# ELM0 register map
Vendor: Texas Instruments
Peripheral module from a debugger description file (folder J7VCL).
Registers are 32-bit, read-only, reset values left out (the file's numbers can be read two ways) unless marked. A register's access mark holds for its fields unless they carry their own. Offsets are as the file gives them; lines under a group give offsets from that group; [hi:lo] are bit positions; {n}, {i} and the like mark numbered series; 'fields as' and 'values as' point back to an identical list; <NAME> marks a mode.

## ELM0
0x5380000 ELM_REVISION — This register contains the IP revision code. (A write to or reset of this register has no effect.)
  [31:0] REVISION — TI internal data. Identifies revision of peripheral.
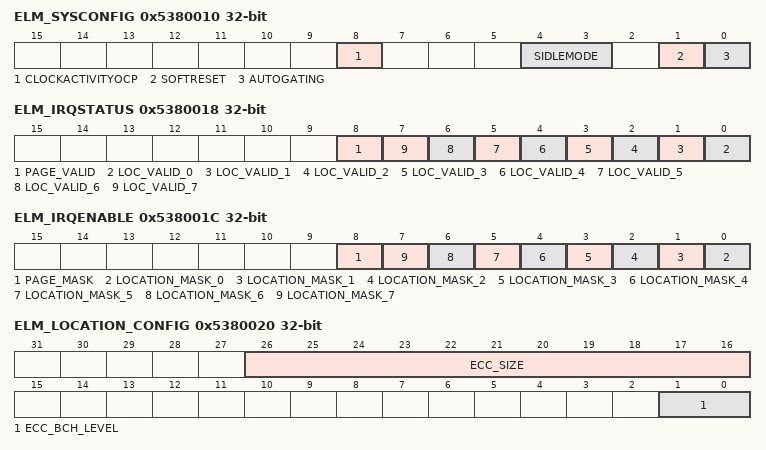
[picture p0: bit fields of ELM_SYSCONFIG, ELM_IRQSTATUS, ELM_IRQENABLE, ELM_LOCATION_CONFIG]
0x5380010 ELM_SYSCONFIG access per field — This register controls ELM local power management and software reset. Some of the ELM features described in this section may not be supported on this family of devices. For more information, see , ELM Not Supported Features.
  [8] CLOCKACTIVITYOCP rw — ELM_FICLK activity when module is in IDLE mode 0h (R/W) = ELM_FICLK can be switched off. 1h (R/W) = ELM_FICLK is maintained.
  [4:3] SIDLEMODE rw — Slave interface power management (clock stop req/ack control) 0h (R/W) = Force-idle. A clock stop request is acknowledged unconditionally and immediately 1h (R/W) = No-idle. A clock stop request is never acknowledged. 2h (R/W) = Smart-idle. The acknowledgment to a clock stop request is given based on the internal activity. 3h (R/W) = Reserved do not use
  [1] SOFTRESET rw — Module software reset 0h (R/W) = Normal mode 1h (R/W) = Start soft reset sequence.
  [0] AUTOGATING rw — Internal ELM_FICLK gating strategy 0h (R/W) = ELM_FICLK is free-running. 1h (R/W) = Automatic internal ELM_FICLK gating strategy is applied based on the Interconnect interface activity.
0x5380014 ELM_SYSSTATUS — Internal reset monitoring Undefined since: From hardware perspective, the reset state is 0. From software user perspective, when the accessible module is 1.
  [0] RESETDONE — Internal reset monitoring 0h (R) = Reset is ongoing. 1h (R) = Reset is done (completed).
0x5380018 ELM_IRQSTATUS access not given — Interrupt status. This register doubles as a status register for the error-location processes.
  [8] PAGE_VALID — Error-location status for a full page, based on the mask definition (access RW1C)
  [n] LOC_VALID_{n} (n=0..7) — Error-location status for syndrome polynomial {n} (access RW1C)
0x538001C ELM_IRQENABLE access per field — Interrupt enable.
  [8] PAGE_MASK rw — Page interrupt mask bit
  [n] LOCATION_MASK_{n} rw (n=0..7) — Error-location interrupt mask bit for syndrome polynomial {n}
0x5380020 ELM_LOCATION_CONFIG access per field — ECC algorithm parameters.
  [26:16] ECC_SIZE rw — Maximum size of the buffers for which the error-location engine is used, in number of nibbles (4-bit entities)
  [1:0] ECC_BCH_LEVEL rw — Error correction level
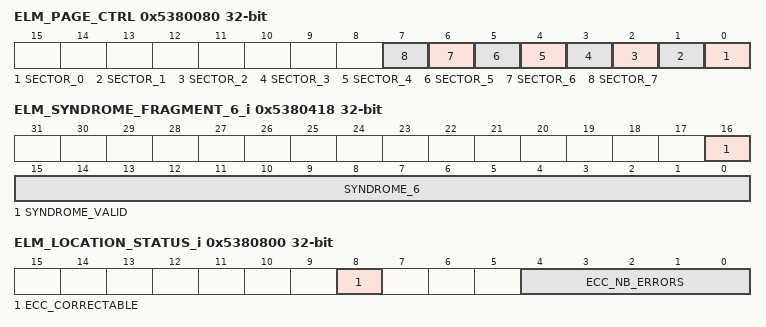
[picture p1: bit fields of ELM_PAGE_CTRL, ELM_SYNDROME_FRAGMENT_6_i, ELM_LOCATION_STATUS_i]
0x5380080 ELM_PAGE_CTRL access per field — Page definition.
  [n] SECTOR_{n} rw (n=0..7) — Set to 1 if syndrome polynomial {n} is part of the page in page mode. Must be 0 in continuous mode.
{0x5380400+4i} ELM_SYNDROME_FRAGMENT_{i}_i rw (i=0..2) — Input syndrome polynomial bits {32i} to {32i+31}. Offset = {4i+400}h + (i * 40h), where: i = 0 to 7
  [31:0] SYNDROME_{i} — Syndrome bits {32i} to {32i+31}
0x538040C ELM_SYNDROME_FRAGMENT_3_i rw — Input syndrome polynomial bits 96 to 127. Offset = 40Ch + (i * 40h), where: i = 0 to 7
  [31:0] SYNDROME_3 — Syndrome bits 96 to 127
0x5380410 ELM_SYNDROME_FRAGMENT_4_i rw — Input syndrome polynomial bits 128 to 159. Offset = 410h + (i * 40h), where: i = 0 to 7
  [31:0] SYNDROME_4 — Syndrome bits 128 to 159
0x5380414 ELM_SYNDROME_FRAGMENT_5_i rw — Input syndrome polynomial bits 160 to 191. Offset = 414h + (i * 40h), where: i = 0 to 7
  [31:0] SYNDROME_5 — Syndrome bits 160 to 191
0x5380418 ELM_SYNDROME_FRAGMENT_6_i access per field — Input syndrome polynomial bits 192 to 207. Offset = 418h + (i * 40h), where: i = 0 to 7
  [16] SYNDROME_VALID rw — Syndrome valid bit
  [15:0] SYNDROME_6 rw — Syndrome bits 192 to 207
0x5380800 ELM_LOCATION_STATUS_i — Exit status for the syndrome polynomial processing. Offset = 800h + (i * 100h), where: i = 0 to 7
  [8] ECC_CORRECTABLE — Error-location process exit status
  [4:0] ECC_NB_ERRORS — Number of errors detected and located
{0x5380880+4i} ELM_ERROR_LOCATION_{i}_i (i=0..2) — Error-location register {i}. Offset = {4i+880}h + (i * 100h), where: i = 0 to 7
  [12:0] ECC_ERROR_LOCATION — Error-location bit address
0x538088C ELM_ERROR_LOCATION_3_i — Error-location register 3. Offset = 88Ch + (i * 100h), where: i = 0 to 7
  [12:0] ECC_ERROR_LOCATION — Error-location bit address
{0x5380880+4i} ELM_ERROR_LOCATION_{i}_i (i=4..6) — Error-location register {i}. Offset = {4i+874}h + (i * 100h), where: i = 0 to 7
  [12:0] ECC_ERROR_LOCATION — Error-location bit address
0x538089C ELM_ERROR_LOCATION_7_i — Error-location register 7. Offset = 89Ch + (i * 100h), where: i = 0 to 7
  [12:0] ECC_ERROR_LOCATION — Error-location bit address
{0x5380880+4i} ELM_ERROR_LOCATION_{i}_i (i=8..10) — Error-location register {i}. Offset = 8A{4i-32}h + (i * 100h), where: i = 0 to 7
  [12:0] ECC_ERROR_LOCATION — Error-location bit address
0x53808AC ELM_ERROR_LOCATION_11_i — Error-location register 11. Offset = 8ACh + (i * 100h), where: i = 0 to 7
  [12:0] ECC_ERROR_LOCATION — Error-location bit address
{0x5380880+4i} ELM_ERROR_LOCATION_{i}_i (i=12..14) — Error-location register {i}. Offset = 8B{4i-48}h + (i * 100h), where: i = 0 to 7
  [12:0] ECC_ERROR_LOCATION — Error-location bit address
0x53808BC ELM_ERROR_LOCATION_15_i — Error-location register 15. Offset = 8BCh + (i * 100h), where: i = 0 to 7
  [12:0] ECC_ERROR_LOCATION — Error-location bit address
